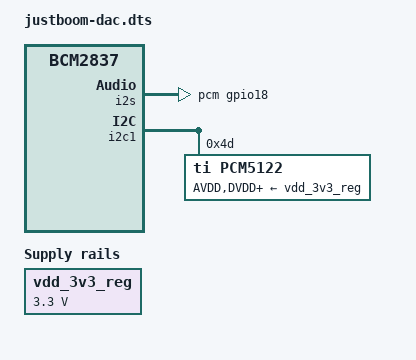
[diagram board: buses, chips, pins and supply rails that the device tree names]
// Definitions for JustBoom DAC
/dts-v1/;
/plugin/;

/ {
	compatible = "brcm,bcm2837";

	fragment@0 {
		target = <&i2s>;
		__overlay__ {
			status = "okay";
			pinctrl-names = "default";
			pinctrl-0 = <&pcm_gpio18>;
		};
	};

	fragment@1 {
		target = <&i2c1>;
		__overlay__ {
			status = "okay";

			pcm5122@4d {
				#sound-dai-cells = <0>;
				compatible = "ti,pcm5122";
				reg = <0x4d>;
				AVDD-supply = <&vdd_3v3_reg>;
				DVDD-supply = <&vdd_3v3_reg>;
				CPVDD-supply = <&vdd_3v3_reg>;
				status = "okay";
			};
		};
	};

	fragment@2 {
		target-path = "/soc";
		__overlay__ {
			sound: sound {
				compatible = "justboom,justboom-dac";
				i2s-controller = <&i2s>;
				status = "okay";
			};
		};
	};

	fragment@3 {
		target-path = "/";
		__overlay__ {
			vdd_3v3_reg: fixedregulator_3v3 {
				compatible = "regulator-fixed";
				regulator-name = "3v3";
				regulator-min-microvolt = <3300000>;
				regulator-max-microvolt = <3300000>;
				regulator-always-on;
			};
		};
	};
};
